AUTOSAR XML (schema 00046)
package /ComponentTypes
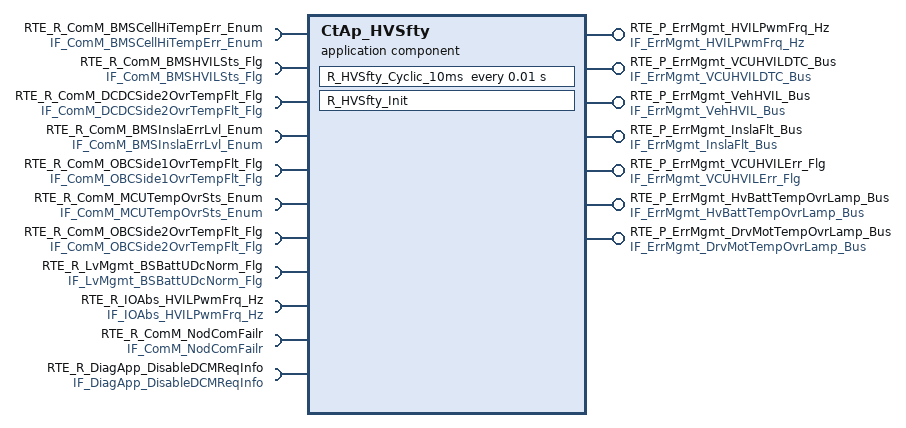
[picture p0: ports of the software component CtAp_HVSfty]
  application sw component type CtAp_HVSfty
    5 x provide port:
      RTE_P_ErrMgmt_HVILPwmFrq_Hz: nonqueued-sender-com-spec{data-element=tec_ErrMgmt_HVILPwmFrq_Hz, init-value=0}, provided-interface=IF_ErrMgmt_HVILPwmFrq_Hz
      RTE_P_ErrMgmt_VCUHVILDTC_Bus: nonqueued-sender-com-spec{data-element=tec_ErrMgmt_VCUHVILDTC_Bus, init-value=fields=[ErrMgmt_MonStatVCUHVIL:0, ErrMgmt_MonResVCUHVIL:0, ErrMgmt_ErrStatVCUHVIL:0, ErrMgmt_ErrResVCUHVIL:0]}, provided-interface=IF_ErrMgmt_VCUHVILDTC_Bus
      RTE_P_ErrMgmt_VehHVIL_Bus: nonqueued-sender-com-spec{data-element=tec_ErrMgmt_VehHVIL_Bus, init-value=fields=[ErrMgmt_MonStatVehHVIL:0, ErrMgmt_MonResVehHVIL:0, ErrMgmt_ErrStatVehHVIL:0, ErrMgmt_ErrResVehHVIL:0]}, provided-interface=IF_ErrMgmt_VehHVIL_Bus
      RTE_P_ErrMgmt_InslaFlt_Bus: nonqueued-sender-com-spec{data-element=tec_ErrMgmt_InslaFlt_Bus, init-value=fields=[ErrMgmt_MonStatVehHVInsla:0, ErrMgmt_MonResVehHVInsla:0, ErrMgmt_ErrStatVehHVInsla:0, ErrMgmt_ErrResVehHVInsla:0]}, provided-interface=IF_ErrMgmt_InslaFlt_Bus
      RTE_P_ErrMgmt_VCUHVILErr_Flg: nonqueued-sender-com-spec{data-element=tec_ErrMgmt_VCUHVILErr_Flg, init-value=0}, provided-interface=IF_ErrMgmt_VCUHVILErr_Flg
    10 x require port:
      RTE_R_ComM_BMSCellHiTempErr_Enum: nonqueued-receiver-com-spec{data-element=tec_ComM_BMSCellHiTempErr_Enum, filter=data-filter-type=ALWAYS, init-value=0}, required-interface=IF_ComM_BMSCellHiTempErr_Enum
      RTE_R_ComM_BMSHVILSts_Flg: nonqueued-receiver-com-spec{data-element=tec_ComM_BMSHVILSts_Flg, filter=data-filter-type=ALWAYS, init-value=0}, required-interface=IF_ComM_BMSHVILSts_Flg
      RTE_R_ComM_DCDCSide2OvrTempFlt_Flg: nonqueued-receiver-com-spec{data-element=tec_ComM_DCDCSide2OvrTempFlt_Flg, filter=data-filter-type=ALWAYS, init-value=0}, required-interface=IF_ComM_DCDCSide2OvrTempFlt_Flg
      RTE_R_ComM_BMSInslaErrLvl_Enum: nonqueued-receiver-com-spec{data-element=tec_ComM_BMSInslaErrLvl_Enum, filter=data-filter-type=ALWAYS, init-value=0}, required-interface=IF_ComM_BMSInslaErrLvl_Enum
      RTE_R_ComM_OBCSide1OvrTempFlt_Flg: nonqueued-receiver-com-spec{data-element=tec_ComM_OBCSide1OvrTempFlt_Flg, filter=data-filter-type=ALWAYS, init-value=0}, required-interface=IF_ComM_OBCSide1OvrTempFlt_Flg
      RTE_R_ComM_MCUTempOvrSts_Enum: nonqueued-receiver-com-spec{data-element=tec_ComM_MCUTempOvrSts_Enum, filter=data-filter-type=ALWAYS, init-value=0}, required-interface=IF_ComM_MCUTempOvrSts_Enum
      RTE_R_ComM_OBCSide2OvrTempFlt_Flg: nonqueued-receiver-com-spec{data-element=tec_ComM_OBCSide2OvrTempFlt_Flg, filter=data-filter-type=ALWAYS, init-value=0}, required-interface=IF_ComM_OBCSide2OvrTempFlt_Flg
      RTE_R_LvMgmt_BSBattUDcNorm_Flg: nonqueued-receiver-com-spec{data-element=tec_LvMgmt_BSBattUDcNorm_Flg, filter=data-filter-type=ALWAYS, init-value=0}, required-interface=IF_LvMgmt_BSBattUDcNorm_Flg
      RTE_R_IOAbs_HVILPwmFrq_Hz: nonqueued-receiver-com-spec{data-element=tec_IOAbs_HVILPwmFrq_Hz, filter=data-filter-type=ALWAYS, init-value=0}, required-interface=IF_IOAbs_HVILPwmFrq_Hz
      RTE_R_ComM_NodComFailr: required-interface=IF_ComM_NodComFailr
        required-com-specs:
          data-element=tec_ComM_ACUNodComFailr_Flg, filter=data-filter-type=ALWAYS, init-value=0
          data-element=tec_ComM_SGWNodComFailr_Flg, filter=data-filter-type=ALWAYS, init-value=0
          data-element=tec_ComM_CGWNodComFailr_Flg, filter=data-filter-type=ALWAYS, init-value=0
          data-element=tec_ComM_TCUNodComFailr_Flg, filter=data-filter-type=ALWAYS, init-value=0
          data-element=tec_ComM_BCMNodComFailr_Flg, filter=data-filter-type=ALWAYS, init-value=0
          data-element=tec_ComM_PRNDNodComFailr_Flg, filter=data-filter-type=ALWAYS, init-value=0
          data-element=tec_ComM_IVINodComFailr_Flg, filter=data-filter-type=ALWAYS, init-value=0
          data-element=tec_ComM_DCDCNodComFailr_Flg, filter=data-filter-type=ALWAYS, init-value=0
          data-element=tec_ComM_OBCNodComFailr_Flg, filter=data-filter-type=ALWAYS, init-value=0
          data-element=tec_ComM_CHIBSNodComFailr_Flg, filter=data-filter-type=ALWAYS, init-value=0
          data-element=tec_ComM_MCUNodComFailr_Flg, filter=data-filter-type=ALWAYS, init-value=0
          data-element=tec_ComM_EVCOMNodComFailr_Flg, filter=data-filter-type=ALWAYS, init-value=0
          data-element=tec_ComM_EPTIBSNodComFailr_Flg, filter=data-filter-type=ALWAYS, init-value=0
          data-element=tec_ComM_DCMNodComFailr_Flg, filter=data-filter-type=ALWAYS, init-value=0
          data-element=tec_ComM_BMSNodComFailr_Flg, filter=data-filter-type=ALWAYS, init-value=0
          data-element=tec_ComM_APTCNodComFailr_Flg, filter=data-filter-type=ALWAYS, init-value=0
          data-element=tec_ComM_ADCUNodComFailr_Flg, filter=data-filter-type=ALWAYS, init-value=0
          data-element=tec_ComM_DCMRRNodComFailr_Flg, filter=data-filter-type=ALWAYS, init-value=0
          data-element=tec_ComM_DCMRLNodComFailr_Flg, filter=data-filter-type=ALWAYS, init-value=0
          data-element=tec_ComM_DCMFRNodComFailr_Flg, filter=data-filter-type=ALWAYS, init-value=0
          data-element=tec_ComM_DCMFLNodComFailr_Flg, filter=data-filter-type=ALWAYS, init-value=0
          data-element=tec_ComM_SGWCHNodComFailr_Flg, init-value=0
    provide port RTE_P_ErrMgmt_HvBattTempOvrLamp_Bus: nonqueued-sender-com-spec{data-element=tec_ErrMgmt_HvBattTempOvrLamp_Bus, init-value=fields=[ErrMgmt_MonStatBMSTempOvr:0, ErrMgmt_MonResBMSTempOvr:0, ErrMgmt_ErrStatBMSTempOvr:0, ErrMgmt_ErrResBMSTempOvr:0]}, provided-interface=IF_ErrMgmt_HvBattTempOvrLamp_Bus
    provide port RTE_P_ErrMgmt_DrvMotTempOvrLamp_Bus: nonqueued-sender-com-spec{data-element=tec_ErrMgmt_DrvMotTempOvrLamp_Bus, init-value=fields=[ErrMgmt_MonStatMCUTempOvr:0, ErrMgmt_MonResMCUTempOvr:0, ErrMgmt_ErrStatMCUTempOvr:0, ErrMgmt_ErrResMCUTempOvr:0]}, provided-interface=IF_ErrMgmt_DrvMotTempOvrLamp_Bus
    require port RTE_R_DiagApp_DisableDCMReqInfo: nonqueued-receiver-com-spec{data-element=tec_DiagApp_DisableDCMReqInfo, filter=data-filter-type=ALWAYS, init-value=0}, required-interface=IF_DiagApp_DisableDCMReqInfo
    behavior CtAp_HVSfty_InternalBehavior
      timing event TMT_R_HVSfty_Cyclic_10ms: start-on-event=R_HVSfty_Cyclic_10ms, period=0.01
      init event CtAp_HVSfty_InitEvent: start-on-event=R_HVSfty_Init
      runnable R_HVSfty_Cyclic_10ms
        data-receive-point-by-arguments:
          11 x access:
            REC_RTE_R_ComM_BMSCellHiTempErr_Enum_tec_ComM_BMSCellHiTempErr_Enum: accessed-variable=RTE_R_ComM_BMSCellHiTempErr_Enum.tec_ComM_BMSCellHiTempErr_Enum
            REC_RTE_R_ComM_BMSHVILSts_Flg_tec_ComM_BMSHVILSts_Flg: accessed-variable=RTE_R_ComM_BMSHVILSts_Flg.tec_ComM_BMSHVILSts_Flg
            REC_RTE_R_ComM_BMSInslaErrLvl_Enum_tec_ComM_BMSInslaErrLvl_Enum: accessed-variable=RTE_R_ComM_BMSInslaErrLvl_Enum.tec_ComM_BMSInslaErrLvl_Enum
            REC_RTE_R_ComM_DCDCSide2OvrTempFlt_Flg_tec_ComM_DCDCSide2OvrTempFlt_Flg: accessed-variable=RTE_R_ComM_DCDCSide2OvrTempFlt_Flg.tec_ComM_DCDCSide2OvrTempFlt_Flg
            REC_RTE_R_ComM_MCUTempOvrSts_Enum_tec_ComM_MCUTempOvrSts_Enum: accessed-variable=RTE_R_ComM_MCUTempOvrSts_Enum.tec_ComM_MCUTempOvrSts_Enum
            REC_RTE_R_ComM_OBCSide1OvrTempFlt_Flg_tec_ComM_OBCSide1OvrTempFlt_Flg: accessed-variable=RTE_R_ComM_OBCSide1OvrTempFlt_Flg.tec_ComM_OBCSide1OvrTempFlt_Flg
            REC_RTE_R_ComM_OBCSide2OvrTempFlt_Flg_tec_ComM_OBCSide2OvrTempFlt_Flg: accessed-variable=RTE_R_ComM_OBCSide2OvrTempFlt_Flg.tec_ComM_OBCSide2OvrTempFlt_Flg
            REC_RTE_R_IOAbs_HVILPwmFrq_Hz_tec_IOAbs_HVILPwmFrq_Hz: accessed-variable=RTE_R_IOAbs_HVILPwmFrq_Hz.tec_IOAbs_HVILPwmFrq_Hz
            REC_RTE_R_LvMgmt_BSBattUDcNorm_Flg_tec_LvMgmt_BSBattUDcNorm_Flg: accessed-variable=RTE_R_LvMgmt_BSBattUDcNorm_Flg.tec_LvMgmt_BSBattUDcNorm_Flg
            REC_RTE_R_ComM_NodComFailr_tec_ComM_BMSNodComFailr_Flg: accessed-variable=RTE_R_ComM_NodComFailr.tec_ComM_BMSNodComFailr_Flg
            REC_RTE_R_DiagApp_DisableDCMReqInfo_tec_DiagApp_DisableDCMReqInfo: accessed-variable=RTE_R_DiagApp_DisableDCMReqInfo.tec_DiagApp_DisableDCMReqInfo
        data-send-points:
          7 x access:
            SEND_RTE_P_ErrMgmt_HVILPwmFrq_Hz_tec_ErrMgmt_HVILPwmFrq_Hz: accessed-variable=RTE_P_ErrMgmt_HVILPwmFrq_Hz.tec_ErrMgmt_HVILPwmFrq_Hz
            SEND_RTE_P_ErrMgmt_InslaFlt_Bus_tec_ErrMgmt_InslaFlt_Bus: accessed-variable=RTE_P_ErrMgmt_InslaFlt_Bus.tec_ErrMgmt_InslaFlt_Bus
            SEND_RTE_P_ErrMgmt_VCUHVILDTC_Bus_tec_ErrMgmt_VCUHVILDTC_Bus: accessed-variable=RTE_P_ErrMgmt_VCUHVILDTC_Bus.tec_ErrMgmt_VCUHVILDTC_Bus
            SEND_RTE_P_ErrMgmt_VCUHVILErr_Flg_tec_ErrMgmt_VCUHVILErr_Flg: accessed-variable=RTE_P_ErrMgmt_VCUHVILErr_Flg.tec_ErrMgmt_VCUHVILErr_Flg
            SEND_RTE_P_ErrMgmt_VehHVIL_Bus_tec_ErrMgmt_VehHVIL_Bus: accessed-variable=RTE_P_ErrMgmt_VehHVIL_Bus.tec_ErrMgmt_VehHVIL_Bus
            SEND_RTE_P_ErrMgmt_DrvMotTempOvrLamp_Bus_tec_ErrMgmt_DrvMotTempOvrLamp_Bus: accessed-variable=RTE_P_ErrMgmt_DrvMotTempOvrLamp_Bus.tec_ErrMgmt_DrvMotTempOvrLamp_Bus
            SEND_RTE_P_ErrMgmt_HvBattTempOvrLamp_Bus_tec_ErrMgmt_HvBattTempOvrLamp_Bus: accessed-variable=RTE_P_ErrMgmt_HvBattTempOvrLamp_Bus.tec_ErrMgmt_HvBattTempOvrLamp_Bus
      runnable R_HVSfty_Init
  swc implementation CtAp_HVSfty_Implementation: behavior=CtAp_HVSfty_InternalBehavior
